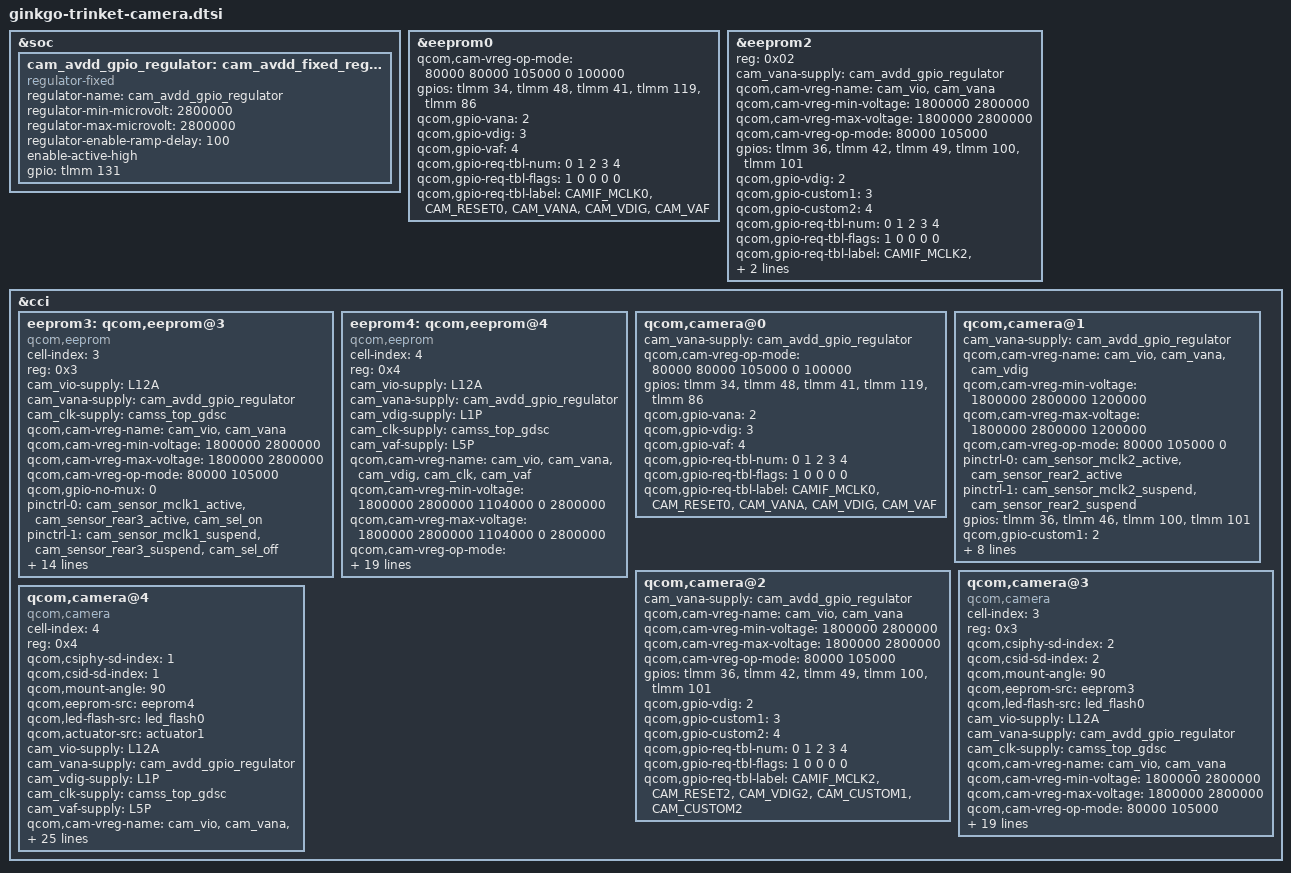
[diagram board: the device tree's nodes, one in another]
&soc {
	cam_avdd_gpio_regulator: cam_avdd_fixed_regulator{
		compatible = "regulator-fixed";
		regulator-name = "cam_avdd_gpio_regulator";
		regulator-min-microvolt = <2800000>;
		regulator-max-microvolt = <2800000>;
		regulator-enable-ramp-delay = <100>;
		enable-active-high;
		gpio = <&tlmm 131 0>;
	};
};

&eeprom0 {
	qcom,cam-vreg-op-mode = <80000 80000 105000 0 100000>;
	gpios = <&tlmm 34 0>,
		<&tlmm 48 0>,
		<&tlmm 41 0>,
		<&tlmm 119 0>,
		<&tlmm 86 0>;
	qcom,gpio-vana = <2>;
	qcom,gpio-vdig = <3>;
	qcom,gpio-vaf = <4>;
	qcom,gpio-req-tbl-num = <0 1 2 3 4>;
	qcom,gpio-req-tbl-flags = <1 0 0 0 0>;

	qcom,gpio-req-tbl-label = "CAMIF_MCLK0",
		"CAM_RESET0",
		"CAM_VANA",
		"CAM_VDIG",
		"CAM_VAF";
};

&eeprom2 {
	/delete-property/ cam_vdig-supply;
	/delete-property/ qcom,sensor-position;
	/delete-property/ qcom,gpio-vana;

	reg = <0x02>;
	cam_vana-supply = <&cam_avdd_gpio_regulator>;
	qcom,cam-vreg-name = "cam_vio", "cam_vana";
	qcom,cam-vreg-min-voltage = <1800000 2800000>;
	qcom,cam-vreg-max-voltage = <1800000 2800000>;
	qcom,cam-vreg-op-mode = <80000 105000>;

	gpios = <&tlmm 36 0>,
		<&tlmm 42 0>,
		<&tlmm 49 0>,
		<&tlmm 100 0>,
		<&tlmm 101 0>;

	qcom,gpio-vdig = <2>;
	qcom,gpio-custom1 = <3>;
	qcom,gpio-custom2 = <4>;
	qcom,gpio-req-tbl-num = <0 1 2 3 4>;
	qcom,gpio-req-tbl-flags = <1 0 0 0 0>;
	qcom,gpio-req-tbl-label = "CAMIF_MCLK2",
		"CAM_RESET2",
		"CAM_VDIG2",
		"CAM_CUSTOM1",
		"CAM_CUSTOM2";
};

&cci {
	/delete-node/ eeprom1;

	//back 8M eeprom3
	eeprom3: qcom,eeprom@3 {
		cell-index = <3>;
		reg = <0x3>;
		compatible = "qcom,eeprom";

		cam_vio-supply = <&L12A>;
		cam_vana-supply = <&cam_avdd_gpio_regulator>;
		cam_clk-supply = <&camss_top_gdsc>;

		qcom,cam-vreg-name = "cam_vio", "cam_vana";
		qcom,cam-vreg-min-voltage = <1800000 2800000>;
		qcom,cam-vreg-max-voltage = <1800000 2800000>;
		qcom,cam-vreg-op-mode = <80000 105000>;

		qcom,gpio-no-mux = <0>;
		pinctrl-names = "cam_default", "cam_suspend";
		pinctrl-0 = <&cam_sensor_mclk1_active
				 &cam_sensor_rear3_active
				&cam_sel_on>;
		pinctrl-1 = <&cam_sensor_mclk1_suspend
				 &cam_sensor_rear3_suspend
				&cam_sel_off>;
		gpios = <&tlmm 35 0>,
			<&tlmm 45 0>,
			<&tlmm 49 0>,
			<&tlmm 123 0>;
		qcom,gpio-reset = <1>;
		qcom,gpio-vdig = <2>;
		qcom,gpio-custom1 = <3>;
		qcom,gpio-req-tbl-num = <0 1 2 3>;
		qcom,gpio-req-tbl-flags = <1 0 0 0>;
		qcom,gpio-req-tbl-label = "CAMIF_MCLK1",
					  "CAM_RESET3",
					"CAM_VDIG3",
					"CAM_CUSTOM1";
		qcom,sensor-position = <0>;
		qcom,sensor-mode = <0>;
		qcom,cci-master = <1>;
		status = "ok";
		clocks = <&clock_gcc GCC_CAMSS_MCLK1_CLK_SRC>,
		    <&clock_gcc GCC_CAMSS_MCLK1_CLK>;
		clock-names = "cam_src_clk", "cam_clk";
		qcom,clock-rates = <24000000 0>;
	};

	//back macro
	eeprom4: qcom,eeprom@4 {
		cell-index = <4>;
		compatible = "qcom,eeprom";
		reg = <0x4>;

		cam_vio-supply = <&L12A>;
		cam_vana-supply = <&cam_avdd_gpio_regulator>;
		cam_vdig-supply = <&L1P>;
		cam_clk-supply = <&camss_top_gdsc>;
		cam_vaf-supply = <&L5P>;
		qcom,cam-vreg-name = "cam_vio", "cam_vana", "cam_vdig",
				"cam_clk", "cam_vaf";
		qcom,cam-vreg-min-voltage =  <1800000 2800000 1104000 0 2800000>;
		qcom,cam-vreg-max-voltage = <1800000 2800000 1104000 0 2800000>;
		qcom,cam-vreg-op-mode =<80000 80000 105000 0 100000>;

		qcom,gpio-no-mux = <0>;
		pinctrl-names = "cam_default", "cam_suspend";
		pinctrl-0 = <&cam_sensor_mclk3_active
				 &cam_sensor_rear4_active>;
		pinctrl-1 = <&cam_sensor_mclk3_suspend
				 &cam_sensor_rear4_suspend>;
		gpios = <&tlmm 44 0>,
			<&tlmm 47 0>,
			<&tlmm 86 0>;
		qcom,gpio-reset = <1>;
		qcom,gpio-vaf = <2>;
		qcom,gpio-req-tbl-num = <0 1 2>;
		qcom,gpio-req-tbl-flags = <1 0 0>;
		qcom,gpio-req-tbl-label = "CAMIF_MCLK4",
					  "CAM_RESET4",
					"CAM_VAF1";

		qcom,sensor-position = <0>;
		qcom,sensor-mode = <0>;
		qcom,cci-master = <1>;
		status = "ok";
		clocks = <&clock_gcc GCC_CAMSS_MCLK3_CLK_SRC>,
			<&clock_gcc GCC_CAMSS_MCLK3_CLK>;
		clock-names = "cam_src_clk", "cam_clk";
		qcom,clock-rates = <24000000 0>;
	};

	qcom,camera@0 {
		cam_vana-supply = <&cam_avdd_gpio_regulator>;
		qcom,cam-vreg-op-mode = <80000 80000 105000 0 100000>;
		gpios = <&tlmm 34 0>,
			<&tlmm 48 0>,
			<&tlmm 41 0>,
			<&tlmm 119 0>,
			<&tlmm 86 0>;
		qcom,gpio-vana = <2>;
		qcom,gpio-vdig = <3>;
		qcom,gpio-vaf = <4>;
		qcom,gpio-req-tbl-num = <0 1 2 3 4>;
		qcom,gpio-req-tbl-flags = <1 0 0 0 0>;

		qcom,gpio-req-tbl-label = "CAMIF_MCLK0",
			"CAM_RESET0",
			"CAM_VANA",
			"CAM_VDIG",
			"CAM_VAF";
	};

	//back aux
	qcom,camera@1 {
		/delete-property/ qcom,actuator-src;
		/delete-property/ qcom,eeprom-src;
		/delete-property/ cam_vaf-supply;
		/delete-property/ qcom,gpio-vdig;
		/delete-property/ qcom,gpio-vana;

		cam_vana-supply = <&cam_avdd_gpio_regulator>;
		qcom,cam-vreg-name = "cam_vio", "cam_vana", "cam_vdig";
		qcom,cam-vreg-min-voltage = <1800000 2800000 1200000>;
		qcom,cam-vreg-max-voltage = <1800000 2800000 1200000>;
		qcom,cam-vreg-op-mode = <80000 105000 0>;

		pinctrl-0 = <&cam_sensor_mclk2_active
			&cam_sensor_rear2_active>;

		pinctrl-1 = <&cam_sensor_mclk2_suspend
			&cam_sensor_rear2_suspend>;

		gpios = <&tlmm 36 0>,
			<&tlmm 46 0>,
			<&tlmm 100 0>,
			<&tlmm 101 0>;
		qcom,gpio-custom1 = <2>;
		qcom,gpio-custom2 = <3>;
		qcom,gpio-req-tbl-num = <0 1 2 3>;
		qcom,gpio-req-tbl-flags = <1 0 0 0>;

		qcom,gpio-req-tbl-label = "CAMIF_MCLK1",
			"CAM_RESET1",
			"CAM_CUSTOM1",
			"CAM_CUSTOM2";
		qcom,cci-master = <0>;
		clocks = <&clock_gcc GCC_CAMSS_MCLK2_CLK_SRC>,
			<&clock_gcc GCC_CAMSS_MCLK2_CLK>;
	};

	//front
	qcom,camera@2 {
		/delete-property/ cam_vdig-supply;
		/delete-property/ qcom,gpio-vana;

		cam_vana-supply = <&cam_avdd_gpio_regulator>;
		qcom,cam-vreg-name = "cam_vio", "cam_vana";
		qcom,cam-vreg-min-voltage = <1800000 2800000>;
		qcom,cam-vreg-max-voltage = <1800000 2800000>;
		qcom,cam-vreg-op-mode = <80000 105000>;

		gpios = <&tlmm 36 0>,
			<&tlmm 42 0>,
			<&tlmm 49 0>,
			<&tlmm 100 0>,
			<&tlmm 101 0>;

		qcom,gpio-vdig = <2>;
		qcom,gpio-custom1 = <3>;
		qcom,gpio-custom2 = <4>;
		qcom,gpio-req-tbl-num = <0 1 2 3 4>;
		qcom,gpio-req-tbl-flags = <1 0 0 0 0>;

		qcom,gpio-req-tbl-label = "CAMIF_MCLK2",
			"CAM_RESET2",
			"CAM_VDIG2",
			"CAM_CUSTOM1",
			"CAM_CUSTOM2";
	};

	//back 8M
	qcom,camera@3 {
		cell-index = <3>;
		compatible = "qcom,camera";
		reg = <0x3>;
		qcom,csiphy-sd-index = <2>;
		qcom,csid-sd-index = <2>;
		qcom,mount-angle = <90>;
		qcom,eeprom-src = <&eeprom3>;
		qcom,led-flash-src = <&led_flash0>;
		cam_vio-supply = <&L12A>;
		cam_vana-supply = <&cam_avdd_gpio_regulator>;
		cam_clk-supply = <&camss_top_gdsc>;

		qcom,cam-vreg-name = "cam_vio", "cam_vana";
		qcom,cam-vreg-min-voltage = <1800000 2800000>;
		qcom,cam-vreg-max-voltage = <1800000 2800000>;
		qcom,cam-vreg-op-mode = <80000 105000>;

		qcom,gpio-no-mux = <0>;
		pinctrl-names = "cam_default", "cam_suspend";
		pinctrl-0 = <&cam_sensor_mclk1_active
			&cam_sensor_rear3_active
			&cam_sel_on>;
		pinctrl-1 = <&cam_sensor_mclk1_suspend
			&cam_sensor_rear3_suspend
			&cam_sel_off>;
		gpios = <&tlmm 35 0>,
			<&tlmm 45 0>,
			<&tlmm 49 0>,
			<&tlmm 123 0>;
		qcom,gpio-reset = <1>;
		qcom,gpio-vdig = <2>;
		qcom,gpio-custom1 = <3>;
		qcom,gpio-req-tbl-num = <0 1 2 3>;
		qcom,gpio-req-tbl-flags = <1 0 0 0>;
		qcom,gpio-req-tbl-label = "CAMIF_MCLK1",
			"CAM_RESET3",
			"CAM_VDIG3",
			"CAM_CUSTOM1";
		qcom,sensor-position = <0>;
		qcom,sensor-mode = <0>;
		qcom,cci-master = <1>;
		status = "ok";
		clocks = <&clock_gcc GCC_CAMSS_MCLK1_CLK_SRC>,
			<&clock_gcc GCC_CAMSS_MCLK1_CLK>;
		clock-names = "cam_src_clk", "cam_clk";
		qcom,clock-rates = <24000000 0>;
	};

	//back macro
	qcom,camera@4 {
		cell-index = <4>;
		compatible = "qcom,camera";
		reg = <0x4>;
		qcom,csiphy-sd-index = <1>;
		qcom,csid-sd-index = <1>;
		qcom,mount-angle = <90>;
		qcom,eeprom-src = <&eeprom4>;
		qcom,led-flash-src = <&led_flash0>;
		qcom,actuator-src = <&actuator1>;

		cam_vio-supply = <&L12A>;
		cam_vana-supply = <&cam_avdd_gpio_regulator>;
		cam_vdig-supply = <&L1P>;
		cam_clk-supply = <&camss_top_gdsc>;
		cam_vaf-supply = <&L5P>;
		qcom,cam-vreg-name = "cam_vio", "cam_vana", "cam_vdig",
			"cam_clk", "cam_vaf";
		qcom,cam-vreg-min-voltage =  <1800000 2800000 1104000 0 2800000>;
		qcom,cam-vreg-max-voltage = <1800000 2800000 1104000 0 2800000>;
		qcom,cam-vreg-op-mode =<80000 80000 105000 0 100000>;

		qcom,gpio-no-mux = <0>;
		pinctrl-names = "cam_default", "cam_suspend";
		pinctrl-0 = <&cam_sensor_mclk3_active
			&cam_sensor_rear4_active>;
		pinctrl-1 = <&cam_sensor_mclk3_suspend
			&cam_sensor_rear4_suspend>;
		gpios = <&tlmm 44 0>,
			<&tlmm 47 0>,
			<&tlmm 86 0>;
		qcom,gpio-reset = <1>;
		qcom,gpio-vaf = <2>;
		qcom,gpio-req-tbl-num = <0 1 2>;
		qcom,gpio-req-tbl-flags = <1 0 0>;
		qcom,gpio-req-tbl-label = "CAMIF_MCLK4",
			"CAM_RESET4",
			"CAM_VAF1";
		qcom,sensor-position = <0>;
		qcom,sensor-mode = <0>;
		qcom,cci-master = <1>;
		status = "ok";
		clocks = <&clock_gcc GCC_CAMSS_MCLK3_CLK_SRC>,
			<&clock_gcc GCC_CAMSS_MCLK3_CLK>;
		clock-names = "cam_src_clk", "cam_clk";
		qcom,clock-rates = <24000000 0>;
	};
};
